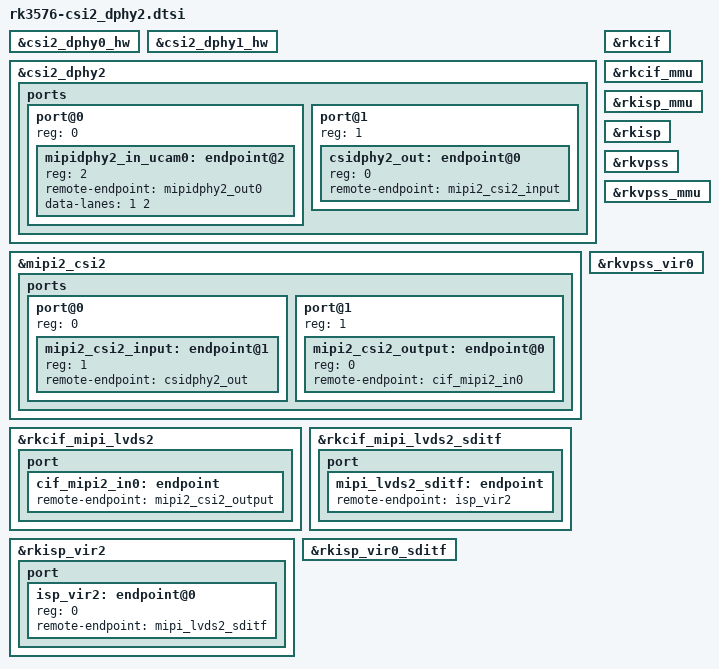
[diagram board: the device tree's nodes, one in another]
&csi2_dphy0_hw {
	status = "okay";
};

&csi2_dphy1_hw {
	status = "okay";
};

&csi2_dphy2 {
	status = "okay";

	ports {
		#address-cells = <1>;
		#size-cells = <0>;

		port@0 {
			reg = <0>;
			#address-cells = <1>;
			#size-cells = <0>;

			mipidphy2_in_ucam0: endpoint@2 {
				reg = <2>;
				remote-endpoint = <&mipidphy2_out0>;
				data-lanes = <1 2>;
			};
		};

		port@1 {
			reg = <1>;
			#address-cells = <1>;
			#size-cells = <0>;

			csidphy2_out: endpoint@0 {
				reg = <0>;
				remote-endpoint = <&mipi2_csi2_input>;
			};
		};
	};
};

&mipi2_csi2 {
	status = "okay";

	ports {
		#address-cells = <1>;
		#size-cells = <0>;

		port@0 {
			reg = <0>;
			#address-cells = <1>;
			#size-cells = <0>;

			mipi2_csi2_input: endpoint@1 {
				reg = <1>;
				remote-endpoint = <&csidphy2_out>;
			};
		};

		port@1 {
			reg = <1>;
			#address-cells = <1>;
			#size-cells = <0>;

			mipi2_csi2_output: endpoint@0 {
				reg = <0>;
				remote-endpoint = <&cif_mipi2_in0>;
			};
		};
	};
};

&rkcif {
	status = "okay";
};

&rkcif_mmu {
	status = "okay";
};

&rkcif_mipi_lvds2 {
	status = "okay";

	port {
		cif_mipi2_in0: endpoint {
		    remote-endpoint = <&mipi2_csi2_output>;
		};
	};
};

&rkcif_mipi_lvds2_sditf {
	status = "okay";

	port {
		mipi_lvds2_sditf: endpoint {
			remote-endpoint = <&isp_vir2>;
		};
	};
};

&rkisp_mmu {
	status = "okay";
};

&rkisp {
	status = "okay";
};

&rkisp_vir2 {
	status = "okay";

	port {
		#address-cells = <1>;
		#size-cells = <0>;

		isp_vir2: endpoint@0 {
			reg = <0>;
			remote-endpoint = <&mipi_lvds2_sditf>;
		};
	};
};

&rkisp_vir0_sditf {
	status = "okay";
};

&rkvpss {
	status = "okay";
};

&rkvpss_mmu {
	status = "okay";
};

&rkvpss_vir0 {
	status = "okay";
};
